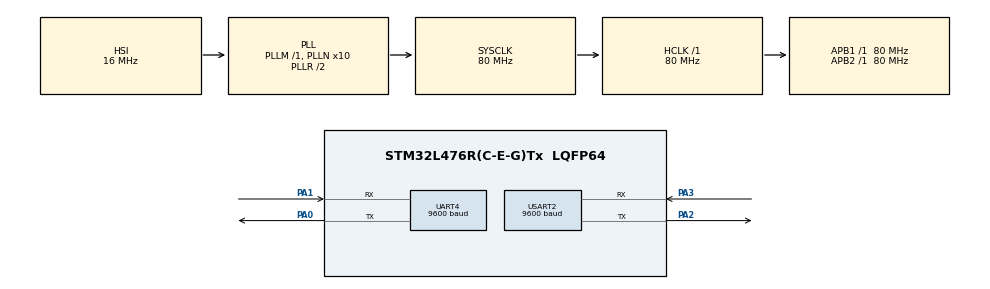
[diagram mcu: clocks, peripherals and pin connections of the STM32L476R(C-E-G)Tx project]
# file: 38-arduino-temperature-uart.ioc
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Mcu.Family=STM32L4
Mcu.Name=STM32L476R(C-E-G)Tx
Mcu.Package=LQFP64
NVIC.PriorityGroup=NVIC_PRIORITYGROUP_4
PA0.Mode=Asynchronous
PA0.Signal=UART4_TX
PA1.Mode=Asynchronous
PA1.Signal=UART4_RX
PA2.Mode=Asynchronous
PA2.Signal=USART2_TX
PA3.Mode=Asynchronous
PA3.Signal=USART2_RX
ProjectManager.HeapSize=0x200
ProjectManager.StackSize=0x400
ProjectManager.TargetToolchain=STM32CubeIDE
RCC.ADCFreq_Value=64000000
RCC.AHBFreq_Value=80000000
RCC.APB1Freq_Value=80000000
RCC.APB1TimFreq_Value=80000000
RCC.APB2Freq_Value=80000000
RCC.APB2TimFreq_Value=80000000
RCC.CortexFreq_Value=80000000
RCC.HCLKFreq_Value=80000000
RCC.HSE_VALUE=8000000
RCC.HSI_VALUE=16000000
RCC.LSE_VALUE=32768
RCC.MSI_VALUE=4000000
RCC.PLLN=10
RCC.PLLSourceVirtual=RCC_PLLSOURCE_HSI
RCC.PREFETCH_ENABLE=1
RCC.SYSCLKFreq_VALUE=80000000
RCC.SYSCLKSource=RCC_SYSCLKSOURCE_PLLCLK
RCC.USBFreq_Value=64000000
RCC.VCOOutputFreq_Value=160000000
UART4.BaudRate=9600
USART2.BaudRate=9600
USART2.VirtualMode-Asynchronous=VM_ASYNC
board=NUCLEO-L476RG

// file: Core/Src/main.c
/* USER CODE BEGIN Header */
/**
  ******************************************************************************
  * @file           : main.c
  * @brief          : Main program body
  ******************************************************************************
  * @attention
  *
  * Copyright (c) 2025 STMicroelectronics.
  * All rights reserved.
  *
  * This software is licensed under terms that can be found in the LICENSE file
  * in the root directory of this software component.
  * If no LICENSE file comes with this software, it is provided AS-IS.
  *
  ******************************************************************************
  */
/* USER CODE END Header */
#include "main.h"

/* USER CODE BEGIN Includes */
#include "string.h"    //for strlen()
#include "stdio.h"    //for sprintf()
/* USER CODE END Includes */

UART_HandleTypeDef huart4;
UART_HandleTypeDef huart2;

void SystemClock_Config(void);
static void MX_GPIO_Init(void);
static void MX_USART2_UART_Init(void);
static void MX_UART4_Init(void);

/* USER CODE BEGIN 0 */

char read_buffer[2], text_buffer[30];
int Temperature;

/* USER CODE END 0 */

int main(void)
{

  /* MCU Configuration--------------------------------------------------------*/

  /* Reset of all peripherals, Initializes the Flash interface and the Systick. */
  HAL_Init();

  /* Configure the system clock */
  SystemClock_Config();

  /* Initialize all configured peripherals */
  MX_GPIO_Init();
  MX_USART2_UART_Init();
  MX_UART4_Init();

  /* Infinite loop */
  /* USER CODE BEGIN WHILE */
  while (1)
  {
	  HAL_UART_Receive(&huart4, (uint8_t*)read_buffer, 2, HAL_MAX_DELAY);    //receive temperature value from Arduino
	  Temperature = 10*(read_buffer[0]-'0') + (read_buffer[1]-'0');    //convert ASCII character to integer
	  sprintf(text_buffer, "Arduino Temperature = %i\n\r", Temperature);    //convert data format
	  HAL_UART_Transmit(&huart2, (uint8_t*)text_buffer, strlen(text_buffer), HAL_MAX_DELAY);    //transmit text by UART
	  HAL_Delay(500);    //delay

    /* USER CODE END WHILE */

  }
}

void SystemClock_Config(void)
{
  RCC_OscInitTypeDef RCC_OscInitStruct = {0};
  RCC_ClkInitTypeDef RCC_ClkInitStruct = {0};

  /** Configure the main internal regulator output voltage
  */
  if (HAL_PWREx_ControlVoltageScaling(PWR_REGULATOR_VOLTAGE_SCALE1) != HAL_OK)
  {
    Error_Handler();
  }

  /** Initializes the RCC Oscillators according to the specified parameters
  * in the RCC_OscInitTypeDef structure.
  */
  RCC_OscInitStruct.OscillatorType = RCC_OSCILLATORTYPE_HSI;
  RCC_OscInitStruct.HSIState = RCC_HSI_ON;
  RCC_OscInitStruct.HSICalibrationValue = RCC_HSICALIBRATION_DEFAULT;
  RCC_OscInitStruct.PLL.PLLState = RCC_PLL_ON;
  RCC_OscInitStruct.PLL.PLLSource = RCC_PLLSOURCE_HSI;
  RCC_OscInitStruct.PLL.PLLM = 1;
  RCC_OscInitStruct.PLL.PLLN = 10;
  RCC_OscInitStruct.PLL.PLLP = RCC_PLLP_DIV7;
  RCC_OscInitStruct.PLL.PLLQ = RCC_PLLQ_DIV2;
  RCC_OscInitStruct.PLL.PLLR = RCC_PLLR_DIV2;
  if (HAL_RCC_OscConfig(&RCC_OscInitStruct) != HAL_OK)
  {
    Error_Handler();
  }

  /** Initializes the CPU, AHB and APB buses clocks
  */
  RCC_ClkInitStruct.ClockType = RCC_CLOCKTYPE_HCLK|RCC_CLOCKTYPE_SYSCLK
                              |RCC_CLOCKTYPE_PCLK1|RCC_CLOCKTYPE_PCLK2;
  RCC_ClkInitStruct.SYSCLKSource = RCC_SYSCLKSOURCE_PLLCLK;
  RCC_ClkInitStruct.AHBCLKDivider = RCC_SYSCLK_DIV1;
  RCC_ClkInitStruct.APB1CLKDivider = RCC_HCLK_DIV1;
  RCC_ClkInitStruct.APB2CLKDivider = RCC_HCLK_DIV1;

  if (HAL_RCC_ClockConfig(&RCC_ClkInitStruct, FLASH_LATENCY_4) != HAL_OK)
  {
    Error_Handler();
  }
}

static void MX_UART4_Init(void)
{

  huart4.Instance = UART4;
  huart4.Init.BaudRate = 9600;
  huart4.Init.WordLength = UART_WORDLENGTH_8B;
  huart4.Init.StopBits = UART_STOPBITS_1;
  huart4.Init.Parity = UART_PARITY_NONE;
  huart4.Init.Mode = UART_MODE_TX_RX;
  huart4.Init.HwFlowCtl = UART_HWCONTROL_NONE;
  huart4.Init.OverSampling = UART_OVERSAMPLING_16;
  huart4.Init.OneBitSampling = UART_ONE_BIT_SAMPLE_DISABLE;
  huart4.AdvancedInit.AdvFeatureInit = UART_ADVFEATURE_NO_INIT;
  if (HAL_UART_Init(&huart4) != HAL_OK)
  {
    Error_Handler();
  }

}

static void MX_USART2_UART_Init(void)
{

  huart2.Instance = USART2;
  huart2.Init.BaudRate = 9600;
  huart2.Init.WordLength = UART_WORDLENGTH_8B;
  huart2.Init.StopBits = UART_STOPBITS_1;
  huart2.Init.Parity = UART_PARITY_NONE;
  huart2.Init.Mode = UART_MODE_TX_RX;
  huart2.Init.HwFlowCtl = UART_HWCONTROL_NONE;
  huart2.Init.OverSampling = UART_OVERSAMPLING_16;
  huart2.Init.OneBitSampling = UART_ONE_BIT_SAMPLE_DISABLE;
  huart2.AdvancedInit.AdvFeatureInit = UART_ADVFEATURE_NO_INIT;
  if (HAL_UART_Init(&huart2) != HAL_OK)
  {
    Error_Handler();
  }

}

static void MX_GPIO_Init(void)
{

  /* GPIO Ports Clock Enable */
  __HAL_RCC_GPIOA_CLK_ENABLE();

}

void Error_Handler(void)
{
  __disable_irq();
  while (1)
  {
  }
}
